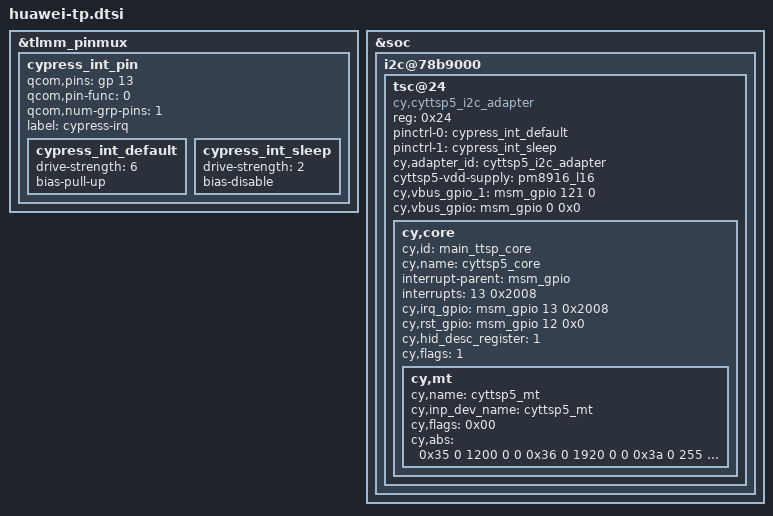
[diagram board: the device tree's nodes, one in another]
/*Add synaptics new driver "Synaptics DSX I2C V2.0"*/
/*Change i2c frepuence from 100kHZ to 400kHZ*/
/*Open fast-relax config for better gesture performance*/
&tlmm_pinmux {
	cypress_int_pin {
		qcom,pins = <&gp 13>;
		qcom,pin-func = <0>;
		qcom,num-grp-pins = <1>;
		label = "cypress-irq";
		cypress_int_default: cypress_int_default {
			drive-strength = <6>;
			bias-pull-up;
		};
		cypress_int_sleep: cypress_int_sleep {
			drive-strength = <2>;
			bias-disable;
		};
	};
};
&soc {
	/*Add cypress TP*/
	i2c@78b9000 {
		status = "ok";
		tsc@24 {
			compatible = "cy,cyttsp5_i2c_adapter";
			reg = <0x24>;
			pinctrl-names = "int_default","int_sleep";
			pinctrl-0 = <&cypress_int_default>;
			pinctrl-1 = <&cypress_int_sleep>;
			cy,adapter_id = "cyttsp5_i2c_adapter";
			cyttsp5-vdd-supply = <&pm8916_l16>;
			cy,vbus_gpio_1 = <&msm_gpio 121 0>;
			cy,vbus_gpio = <&msm_gpio 0 0x0>;
			cy,core {
				cy,id = "main_ttsp_core";
				cy,name = "cyttsp5_core";
				interrupt-parent = <&msm_gpio>;
				interrupts = <13 0x2008>;
				cy,irq_gpio = <&msm_gpio 13 0x2008>;
				cy,rst_gpio = <&msm_gpio 12 0x0>;
				cy,hid_desc_register = <1>;
				cy,flags = <1>;
				cy,mt {
					cy,name = "cyttsp5_mt";
					cy,inp_dev_name = "cyttsp5_mt";
					cy,flags = <0x00>;
					cy,abs =
						/* ABS_MT_POSITION_X, CY_ABS_MIN_X, CY_ABS_MAX_X, 0, 0 */
						<0x35 0 1200 0 0
						/* ABS_MT_POSITION_Y, CY_ABS_MIN_Y, CY_ABS_MAX_Y, 0, 0 */
						0x36 0 1920 0 0
						/* ABS_MT_PRESSURE, CY_ABS_MIN_P, CY_ABS_MAX_P, 0, 0 */
						0x3a 0 255 0 0
						/* CY_IGNORE_VALUE, CY_ABS_MIN_W, CY_ABS_MAX_W, 0, 0 */
						0xffff 0 255 0 0
						/* ABS_MT_TRACKING_ID, CY_ABS_MIN_T, CY_ABS_MAX_T, 0, 0 */
						0x39 0 15 0 0
						/* ABS_MT_TOUCH_MAJOR, 0, 255, 0, 0 */
						0x30 0 255 0 0
						/* ABS_MT_TOUCH_MINOR, 0, 255, 0, 0 */
						0x31 0 255 0 0
						/* ABS_MT_ORIENTATION, -128, 127, 0, 0 */
						0x34 0xfffffed7 127 0 0>;
				};
			};
		};
	};	

};

